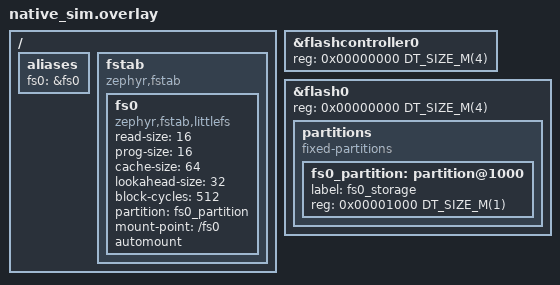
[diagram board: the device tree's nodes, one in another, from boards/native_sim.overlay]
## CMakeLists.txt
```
cmake_minimum_required(VERSION 3.20.0)

set(EL_COMMON_DIR ${CMAKE_CURRENT_SOURCE_DIR}/../../../modules/eerie_leap_rt_core)

set(EXTRA_ZEPHYR_MODULES
    "${CMAKE_CURRENT_SOURCE_DIR}/../../../modules/eerie_leap_lua"
    "${EL_COMMON_DIR}")

# Use Zephyr's build system
find_package(Zephyr REQUIRED HINTS $ENV{ZEPHYR_BASE})
project(test_guid_generator)

# Enable C++23
set(CMAKE_CXX_STANDARD 23)
set(CMAKE_CXX_STANDARD_REQUIRED ON)
set(CMAKE_CXX_EXTENSIONS OFF)

set(APP_SRC_DIR ${CMAKE_CURRENT_SOURCE_DIR}/../../../app/src)
include_directories(${APP_SRC_DIR})

set(APP_SRC_CONFIGURATION_DIR ${APP_SRC_DIR}/configuration)
file(GLOB_RECURSE APP_SRC_CONFIGURATION
  ${APP_SRC_CONFIGURATION_DIR}/*.c
  ${APP_SRC_CONFIGURATION_DIR}/*.cpp
  ${EL_COMMON_DIR}/src/configuration/cbor/traits/system_config_trait.cpp
  ${EL_COMMON_DIR}/src/configuration/cbor/cbor_system_config/*.c
  ${EL_COMMON_DIR}/src/configuration/cbor/traits/adc_config_trait.cpp
  ${EL_COMMON_DIR}/src/configuration/cbor/cbor_adc_config/*.cpp
  ${EL_COMMON_DIR}/src/configuration/cbor/traits/sensors_config_trait.cpp
  ${EL_COMMON_DIR}/src/configuration/cbor/cbor_sensors_config/*.cpp
)

set(APP_SRC_SUBSYS_DIR ${APP_SRC_DIR}/subsys)
file(GLOB_RECURSE APP_SRC_SUBSYS
  ${APP_SRC_SUBSYS_DIR}/device_tree/dt_fs.cpp
  ${APP_SRC_SUBSYS_DIR}/device_tree/dt_logger.cpp
  ${APP_SRC_SUBSYS_DIR}/adc/*.cpp
)

file(GLOB_RECURSE TEST_SOURCES src/*.c src/*.cpp)

# Add all source files to the app target
target_sources(app PRIVATE
  ${APP_SRC_CONFIGURATION}
  ${APP_SRC_SUBSYS}
  ${TEST_SOURCES}
)
```

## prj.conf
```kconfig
CONFIG_ZTEST=y

# Language and Compiler
CONFIG_CPP=y
CONFIG_PICOLIBC=y
CONFIG_STD_CPP2B=y
CONFIG_REQUIRES_FULL_LIBCPP=y
CONFIG_CPP_EXCEPTIONS=y
CONFIG_CPP_RTTI=y

# Logging And Debugging
CONFIG_LOG=y
CONFIG_TEST_RANDOM_GENERATOR=y
CONFIG_THREAD_ANALYZER=y
CONFIG_THREAD_ANALYZER_USE_LOG=y
CONFIG_THREAD_RUNTIME_STATS=y
CONFIG_THREAD_NAME=y
CONFIG_SYS_HEAP_RUNTIME_STATS=y
CONFIG_THREAD_ANALYZER_ISR_STACK_USAGE=n

# Memory
CONFIG_HEAP_MEM_POOL_SIZE=100000

# FS Config
CONFIG_FLASH=y
CONFIG_FLASH_MAP=y
CONFIG_FILE_SYSTEM=y
CONFIG_FILE_SYSTEM_LITTLEFS=y
CONFIG_FILE_SYSTEM_MKFS=y

# CBOR
CONFIG_ZCBOR=y

CONFIG_CRC=y

CONFIG_EERIE_LEAP_RT_CORE=y
CONFIG_EERIE_LEAP_CONFIGURATION=y
CONFIG_EERIE_LEAP_FS=y
CONFIG_EERIE_LEAP_GPIO=y
CONFIG_EERIE_LEAP_LUA_SCRIPT=y
CONFIG_EERIE_LEAP_RANDOM=y
CONFIG_EERIE_LEAP_TIME=y
```

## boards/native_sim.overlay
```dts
/ {
	aliases {
		fs0 = &fs0;
	};

	fstab {
		compatible = "zephyr,fstab";
		fs0: fs0 {
			compatible = "zephyr,fstab,littlefs";
			read-size = <16>;
			prog-size = <16>;
			cache-size = <64>;
			lookahead-size = <32>;
			block-cycles = <512>;
			partition = <&fs0_partition>;
			mount-point = "/fs0";
			automount;
		};
	};
};

&flashcontroller0 {
	reg = <0x00000000 DT_SIZE_M(4)>;  // 4MB flash controller
};

// HEX Flash dump can be found in the duild/flash.bin file
&flash0 {
	reg = <0x00000000 DT_SIZE_M(4)>;  // 4MB total flash

	partitions {
		compatible = "fixed-partitions";
		#address-cells = <1>;
		#size-cells = <1>;

		fs0_partition: partition@1000 {
			label = "fs0_storage";
			reg = <0x00001000 DT_SIZE_M(1)>;  // 0x00001000 offset, 1MB size
		};
	};
};
```

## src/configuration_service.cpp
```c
#include <memory>
#include <zephyr/ztest.h>

#include "utilities/cbor/cbor_helpers.hpp"
#include "configuration/cbor/cbor_system_config/cbor_system_config.h"
#include "configuration/cbor/cbor_sensors_config/cbor_sensors_config.h"
#include "configuration/services/cbor_configuration_service.h"

#include "subsys/device_tree/dt_fs.h"
#include "subsys/fs/services/i_fs_service.h"
#include "subsys/fs/services/fs_service.h"

using namespace eerie_leap::utilities::cbor;
using namespace eerie_leap::configuration::services;
using namespace eerie_leap::subsys::fs::services;
using namespace eerie_leap::subsys::device_tree;

ZTEST_SUITE(configuration_service, NULL, NULL, NULL, NULL, NULL);

ZTEST(configuration_service, test_CborSystemConfig_Save_config_successfully_saved) {
    CborSystemConfig system_config;
    memset(&system_config, 0, sizeof(system_config));

    system_config.device_id = 12;
    system_config.build_number = 22;

    DtFs::InitInternalFs();
    auto fs_service = std::make_shared<FsService>(DtFs::GetInternalFsMp().value());

    fs_service->Format();
    auto system_config_service = std::make_unique<CborConfigurationService<CborSystemConfig>>("system_config", fs_service);

    auto save_res = system_config_service->Save(&system_config);
    zassert_true(save_res);
}

ZTEST(configuration_service, test_CborSystemConfig_Load_config_successfully_saved_and_loaded) {
    CborSystemConfig system_config;
    memset(&system_config, 0, sizeof(system_config));

    system_config.device_id = 14;
    system_config.build_number = 46;

    DtFs::InitInternalFs();
    auto fs_service = std::make_shared<FsService>(DtFs::GetInternalFsMp().value());

    fs_service->Format();
    auto system_config_service = std::make_unique<CborConfigurationService<CborSystemConfig>>("system_config", fs_service);

    auto save_res = system_config_service->Save(&system_config);
    zassert_true(save_res);

    auto loaded_config = system_config_service->Load();
    zassert_true(loaded_config.has_value());
    zassert_equal(loaded_config.value().config->device_id, 14);
    zassert_equal(loaded_config.value().config->build_number, 46);
}

ZTEST(configuration_service, test_CborSensorsConfig_Save_config_successfully_saved) {
    // Create first sensor config
    std::string sensor_1_name = "name 1";
    std::string sensor_1_unit = "km/h";
    std::string sensor_1_description = "";
    CborSensorMetadataConfig metadata_config_1 = {
        .name = CborHelpers::ToZcborString(sensor_1_name),
        .unit = CborHelpers::ToZcborString(sensor_1_unit),
        .description = CborHelpers::ToZcborString(sensor_1_description)
    };

    std::string sensor_1_expression = "({var_d} + {y}) * 4";
    CborSensorConfigurationConfig configuration_config_1(std::allocator_arg, Mrm::GetDefaultPmr());
    configuration_config_1.type = 1;
    configuration_config_1.sampling_rate_ms = 210;
    configuration_config_1.interpolation_method = 1;
    configuration_config_1.channel = 6;
    configuration_config_1.channel_present = true;
    configuration_config_1.calibration_table_present = false;
    configuration_config_1.expression = CborHelpers::ToZcborString(sensor_1_expression);
    configuration_config_1.expression_present = true;

    std::string sensor_1_id = "sensor_1";
    CborSensorConfig sensor_config_1(std::allocator_arg, Mrm::GetDefaultPmr());
    sensor_config_1.id = CborHelpers::ToZcborString(sensor_1_id);
    sensor_config_1.metadata = metadata_config_1;
    sensor_config_1.configuration = configuration_config_1;

    // Create second sensor config
    std::string sensor_2_name = "name 2";
    std::string sensor_2_unit = "m/s";
    std::string sensor_2_description = "";
    CborSensorMetadataConfig metadata_config_2 = {
        .name = CborHelpers::ToZcborString(sensor_2_name),
        .unit = CborHelpers::ToZcborString(sensor_2_unit),
        .description = CborHelpers::ToZcborString(sensor_2_description)
    };

    CborSensorCalibrationDataMap calibration_data_map_2(std::allocator_arg, Mrm::GetDefaultPmr());
    calibration_data_map_2.float32float = {
        { 1.0, 2.0 },
        { 1.1, 2.1 },
        { 1.2, 2.2 },
        { 1.3, 2.3 }
    };

    std::string sensor_2_expression = "({x} - 8 * {var_d}) / {f}";
    CborSensorConfigurationConfig configuration_config_2(std::allocator_arg, Mrm::GetDefaultPmr());
    configuration_config_2.type = 1;
    configuration_config_2.sampling_rate_ms = 250;
    configuration_config_2.interpolation_method = 1;
    configuration_config_2.channel = 6;
    configuration_config_2.channel_present = true;
    configuration_config_2.calibration_table = calibration_data_map_2;
    configuration_config_2.calibration_table_present = true;
    configuration_config_2.expression = CborHelpers::ToZcborString(sensor_2_expression);
    configuration_config_2.expression_present = true;

    std::string sensor_2_id = "sensor_2";
    CborSensorConfig sensor_config_2(std::allocator_arg, Mrm::GetDefaultPmr());
    sensor_config_2.id = CborHelpers::ToZcborString(sensor_2_id);
    sensor_config_2.metadata = metadata_config_2;
    sensor_config_2.configuration = configuration_config_2;

    CborSensorsConfig sensors_config(std::allocator_arg, Mrm::GetDefaultPmr());
    sensors_config.CborSensorConfig_m.push_back(std::move(sensor_config_1));
    sensors_config.CborSensorConfig_m.push_back(std::move(sensor_config_2));

    DtFs::InitInternalFs();
    auto fs_service = std::make_shared<FsService>(DtFs::GetInternalFsMp().value());

    fs_service->Format();
    auto cbor_sensors_config_service = std::make_unique<CborConfigurationService<CborSensorsConfig>>("sensors_config", fs_service);

    auto save_res = cbor_sensors_config_service->Save(&sensors_config);
    zassert_true(save_res);
}

ZTEST(configuration_service, test_CborSensorsConfig_Load_config_successfully_saved_and_loaded) {
    // Create first sensor config
    std::string sensor_1_name = "name 3";
    std::string sensor_1_unit = "km/h";
    std::string sensor_1_description = "";
    CborSensorMetadataConfig metadata_config_1 = {
        .name = CborHelpers::ToZcborString(sensor_1_name),
        .unit = CborHelpers::ToZcborString(sensor_1_unit),
        .description = CborHelpers::ToZcborString(sensor_1_description)
    };

    std::string sensor_1_expression = "({var_d} + {y}) * 4";
    CborSensorConfigurationConfig configuration_config_1(std::allocator_arg, Mrm::GetDefaultPmr());
    configuration_config_1.type = 1;
    configuration_config_1.sampling_rate_ms = 210;
    configuration_config_1.interpolation_method = 1;
    configuration_config_1.channel = 6;
    configuration_config_1.channel_present = true;
    configuration_config_1.calibration_table_present = false;
    configuration_config_1.expression = CborHelpers::ToZcborString(sensor_1_expression);
    configuration_config_1.expression_present = true;

    std::string sensor_1_id = "sensor_3";
    CborSensorConfig sensor_config_1(std::allocator_arg, Mrm::GetDefaultPmr());
    sensor_config_1.id = CborHelpers::ToZcborString(sensor_1_id);
    sensor_config_1.metadata = metadata_config_1;
    sensor_config_1.configuration = configuration_config_1;

    // Create second sensor config
    std::string sensor_2_name = "name 4";
    std::string sensor_2_unit = "m/s";
    std::string sensor_2_description = "Some description 4";
    CborSensorMetadataConfig metadata_config_2 = {
        .name = CborHelpers::ToZcborString(sensor_2_name),
        .unit = CborHelpers::ToZcborString(sensor_2_unit),
        .description = CborHelpers::ToZcborString(sensor_2_description)
    };

    CborSensorCalibrationDataMap calibration_data_map_2(std::allocator_arg, Mrm::GetDefaultPmr());
    calibration_data_map_2.float32float = {
        { 1.0, 2.0 },
        { 1.1, 2.1 },
        { 1.2, 2.2 },
        { 1.3, 2.3 }
    };

    std::string sensor_2_expression = "({x} - 8 * {var_d}) / {f}";
    CborSensorConfigurationConfig configuration_config_2(std::allocator_arg, Mrm::GetDefaultPmr());
    configuration_config_2.type = 1;
    configuration_config_2.sampling_rate_ms = 250;
    configuration_config_2.interpolation_method = 1;
    configuration_config_2.channel = 6;
    configuration_config_2.channel_present = true;
    configuration_config_2.calibration_table = calibration_data_map_2;
    configuration_config_2.calibration_table_present = true;
    configuration_config_2.expression = CborHelpers::ToZcborString(sensor_2_expression);
    configuration_config_2.expression_present = true;

    std::string sensor_2_id = "sensor_4";
    CborSensorConfig sensor_config_2(std::allocator_arg, Mrm::GetDefaultPmr());
    sensor_config_2.id = CborHelpers::ToZcborString(sensor_2_id);
    sensor_config_2.metadata = metadata_config_2;
    sensor_config_2.configuration = configuration_config_2;

    // Create sensors config with both sensors
    CborSensorsConfig sensors_config(std::allocator_arg, Mrm::GetDefaultPmr());
    sensors_config.CborSensorConfig_m.push_back(std::move(sensor_config_1));
    sensors_config.CborSensorConfig_m.push_back(std::move(sensor_config_2));

    // Initialize services
    DtFs::InitInternalFs();
    auto fs_service = std::make_shared<FsService>(DtFs::GetInternalFsMp().value());

    fs_service->Format();
    auto sensors_config_service = std::make_unique<CborConfigurationService<CborSensorsConfig>>("sensors_config", fs_service);

    // Save config
    auto save_res = sensors_config_service->Save(&sensors_config);
    zassert_true(save_res);

    // Load config and verify
    auto loaded_config = sensors_config_service->Load();
    zassert_true(loaded_config.has_value());

    auto loaded_sensors_config = std::move(loaded_config.value().config);
    zassert_equal(loaded_sensors_config->CborSensorConfig_m.size(), 2);

    // Verify first sensor
    zassert_str_equal(CborHelpers::ToStdString(loaded_sensors_config->CborSensorConfig_m[0].id).c_str(), sensor_1_id.c_str());

    zassert_str_equal(CborHelpers::ToStdString(loaded_sensors_config->CborSensorConfig_m[0].metadata.name).c_str(), sensor_1_name.c_str());
    zassert_str_equal(CborHelpers::ToStdString(loaded_sensors_config->CborSensorConfig_m[0].metadata.unit).c_str(), sensor_1_unit.c_str());

    zassert_equal(loaded_sensors_config->CborSensorConfig_m[0].configuration.type, 1);
    zassert_equal(loaded_sensors_config->CborSensorConfig_m[0].configuration.channel, 6);
    zassert_true(loaded_sensors_config->CborSensorConfig_m[0].configuration.channel_present);
    zassert_equal(loaded_sensors_config->CborSensorConfig_m[0].configuration.sampling_rate_ms, 210);
    zassert_false(loaded_sensors_config->CborSensorConfig_m[0].configuration.calibration_table_present);
    zassert_equal(loaded_sensors_config->CborSensorConfig_m[0].configuration.interpolation_method, 1);
    zassert_true(loaded_sensors_config->CborSensorConfig_m[0].configuration.expression_present);
    zassert_str_equal(CborHelpers::ToStdString(loaded_sensors_config->CborSensorConfig_m[0].configuration.expression).c_str(), sensor_1_expression.c_str());

    // Verify second sensor
    zassert_str_equal(CborHelpers::ToStdString(loaded_sensors_config->CborSensorConfig_m[1].id).c_str(), sensor_2_id.c_str());

    zassert_str_equal(CborHelpers::ToStdString(loaded_sensors_config->CborSensorConfig_m[1].metadata.name).c_str(), sensor_2_name.c_str());
    zassert_str_equal(CborHelpers::ToStdString(loaded_sensors_config->CborSensorConfig_m[1].metadata.unit).c_str(), sensor_2_unit.c_str());
    zassert_str_equal(CborHelpers::ToStdString(loaded_sensors_config->CborSensorConfig_m[1].metadata.description).c_str(), sensor_2_description.c_str());

    zassert_equal(loaded_sensors_config->CborSensorConfig_m[1].configuration.type, 1);
    zassert_equal(loaded_sensors_config->CborSensorConfig_m[1].configuration.channel, 6);
    zassert_true(loaded_sensors_config->CborSensorConfig_m[1].configuration.channel_present);
    zassert_equal(loaded_sensors_config->CborSensorConfig_m[1].configuration.sampling_rate_ms, 250);
    zassert_true(loaded_sensors_config->CborSensorConfig_m[1].configuration.calibration_table_present);
    zassert_equal(loaded_sensors_config->CborSensorConfig_m[1].configuration.calibration_table.float32float.size(), 4);
    zassert_equal(loaded_sensors_config->CborSensorConfig_m[1].configuration.calibration_table.float32float[0].float32float_key, 1.0);
    zassert_equal(loaded_sensors_config->CborSensorConfig_m[1].configuration.calibration_table.float32float[0].float32float, 2.0);
    zassert_between_inclusive(loaded_sensors_config->CborSensorConfig_m[1].configuration.calibration_table.float32float[1].float32float_key, 1.09, 1.11);
    zassert_between_inclusive(loaded_sensors_config->CborSensorConfig_m[1].configuration.calibration_table.float32float[1].float32float, 2.09, 2.11);
    zassert_between_inclusive(loaded_sensors_config->CborSensorConfig_m[1].configuration.calibration_table.float32float[2].float32float_key, 1.19, 1.21);
    zassert_between_inclusive(loaded_sensors_config->CborSensorConfig_m[1].configuration.calibration_table.float32float[2].float32float, 2.19, 2.21);
    zassert_between_inclusive(loaded_sensors_config->CborSensorConfig_m[1].configuration.calibration_table.float32float[3].float32float_key, 1.29, 1.31);
    zassert_between_inclusive(loaded_sensors_config->CborSensorConfig_m[1].configuration.calibration_table.float32float[3].float32float, 2.29, 2.31);
    zassert_equal(loaded_sensors_config->CborSensorConfig_m[1].configuration.interpolation_method, 1);
    zassert_true(loaded_sensors_config->CborSensorConfig_m[1].configuration.expression_present);
    zassert_str_equal(CborHelpers::ToStdString(loaded_sensors_config->CborSensorConfig_m[1].configuration.expression).c_str(), sensor_2_expression.c_str());
}
```
